# pse84 register map
Vendor: Infineon Technologies; Series: PSE84; File version: 1.0
CPU: CM33 r0p1, little endian, MPU, FPU, VTOR, 3 interrupt priority bits
Registers are 32-bit, read-write, reset 0x0 unless marked. A register's access mark holds for its fields unless they carry their own. Offsets are from the block's base; [hi:lo] are bit positions; lines under a group give offsets from that group; {n}, {i} and the like mark numbered series; 'fields as' and 'values as' point back to an identical list; <NAME> marks a mode.

## PWRMODE — SRSS Power Mode Control Registers
Base 0x42410000
{0x0+0x10*i} PD[{i}] (i=0..15) group — Power Domain Dependency Sense Register
  0x00 PD_SENSE reset not defined — Dependency Sense Register
    [15:0] PD_ON — Each bit <i> indicates whether PD<j> is directly kept on when PD<i> is on. Indirect dependency is still possible if multiple direct dependencies work together to create a transitive relationship. For example, if PD1 depends upon PD2; and PD2 dpends upon PD3; then PD1 indirectly depends upon PD3 regardless of whether there is a direct dependency from PD3 to PD1. Some bits are implemented as constants, and some bits are implemented as user-configurable registers. Refer to PD_SPT register to see how each bit is implemented.
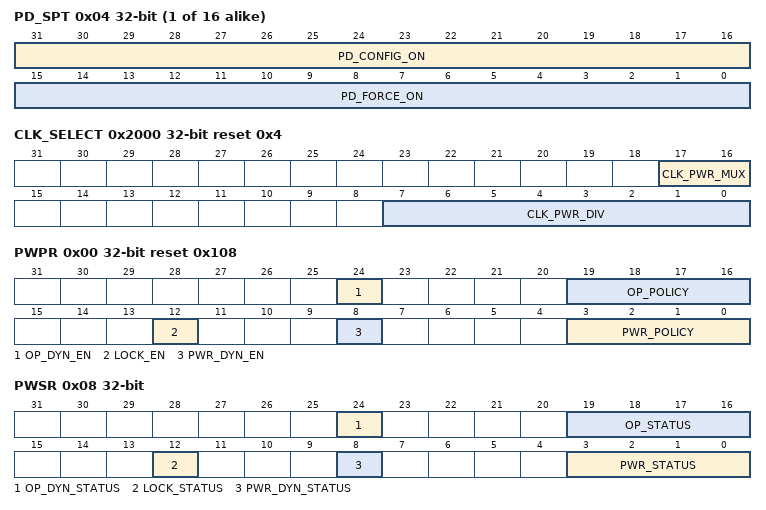
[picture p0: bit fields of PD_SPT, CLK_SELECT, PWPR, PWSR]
  0x04 PD_SPT ro reset not defined — Dependency Support Register
    [31:16] PD_CONFIG_ON — Each bit <i> indicates whether PD<j> can be configured on when PD<i> is on.
    [15:0] PD_FORCE_ON — Each bit <i> indicates whether PD<j> is always kept on when PD<i> is on for sense bits that are not configurable. For configurable bits, this indicates the reset value of the configurable bit.
0x1000 PPU_MAIN group — Power Policy Unit for Active Domain
  0x00 PPU_MAIN group — Power Policy Unit Registers for the main power domain (VCCACT_PD)
    0x00 PWPR reset 0x108 — Power Policy Register
      [24] OP_DYN_EN
      [19:16] OP_POLICY
      [12] LOCK_EN
      [8] PWR_DYN_EN — Power mode dynamic transition enable. For main PPU, keep this bit 1.
      [3:0] PWR_POLICY — Power mode policy. When static power mode transitions are enabled, PWR_DYN_EN is set to 0, this is the target power mode for the PPU. When dynamic power mode transitions are enabled, PWR_DYN_EN is set to 1, this is the minimum power mode for the PPU. This PPU supports the following modes: OFF(0), MEM_RET(2), FULL_RET(5), ON(8). Do not use WARM_RST(9) or other unsupported modes.
    0x04 PMER — Power Mode Emulation Register
      [0] EMU_EN
    0x08 PWSR ro — Power Status Register
      [24] OP_DYN_STATUS
      [19:16] OP_STATUS
      [12] LOCK_STATUS
      [8] PWR_DYN_STATUS — Power mode dynamic transition status. When set to 1 power mode dynamic transitions are enabled. There might be a delay in dynamic transitions becoming active or inactive if the PPU is transitioning when PWR_DYN_EN is programmed.
      [3:0] PWR_STATUS — Power mode status. These bits reflect the current power mode of the PPU. See PPU_PWPR.PWR_POLICY for power mode enumeration.
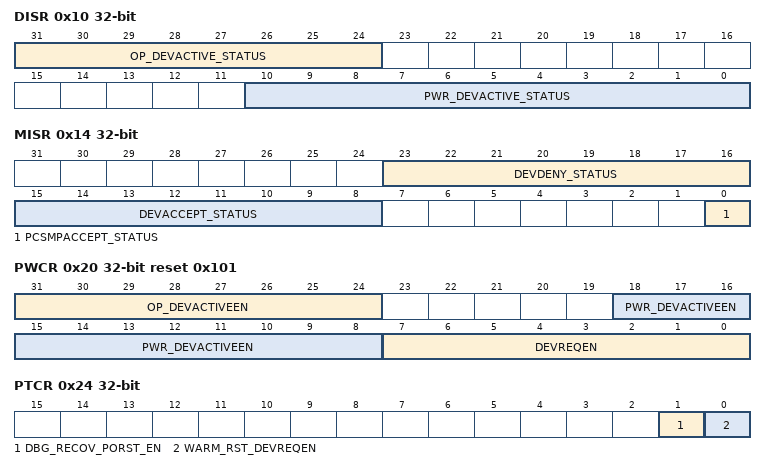
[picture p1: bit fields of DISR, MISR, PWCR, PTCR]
    0x10 DISR ro — Device Interface Input Current Status Register
      [31:24] OP_DEVACTIVE_STATUS
      [10:0] PWR_DEVACTIVE_STATUS — Status of the power mode DEVACTIVE inputs. There is one bit for each device interface Q-Channel DEVQACTIVE. For example, bit 0 is for Q-channel device 0 DEVQACTIVE. Refer to PPU_IDR0.DEVCHAN for device channel enumeration.
    0x14 MISR ro — Miscellaneous Input Current Status Register
      [23:16] DEVDENY_STATUS — Status of the device interface DEVDENY inputs. There is one bit for each device interface DEVQDENY. For example, bit 16 is for Q-Channel 0 DEVQDENY, and bit 17 for Q-Channel 1 DEVQDENY. Refer to PPU_IDR0.DEVCHAN for device channel enumeration.
      [15:8] DEVACCEPT_STATUS — Status of the device interface DEVACCEPT inputs. There is one bit for each device interface DEVQACCEPTn. For example, bit 8 is for Q-Channel 0 DEVQACCEPTn and bit 9 for Q-Channel 1 DEVQACCEPTn. Refer to PPU_IDR0.DEVCHAN for device channel enumeration.
      [0] PCSMPACCEPT_STATUS — The status of the PCSMPACCEPT input.
    0x18 STSR ro — Stored Status Register
      [7:0] STORED_DEVDENY — Status of the DEVDENY signals from the last device interface Q-Channel transition. For Q-Channel: There is one bit for each device interface DEVQDENY. For example, bit 0 is for Q-Channel 0 DEVQDENY, and bit 1 for Q-Channel 1 DEVQDENY. Refer to PPU_DISR.PWR_DEVACTIVE_STATUS for device enumeration.
    0x1C UNLK — Unlock register
      [0] UNLOCK
    0x20 PWCR reset 0x101 — Power Configuration Register
      [31:24] OP_DEVACTIVEEN
      [18:8] PWR_DEVACTIVEEN — These bits enable the power mode DEVACTIVE inputs. When a bit is to 1 the related DEVACTIVE input is enabled, when set to 0 it is disabled. All available bits are reset to 1. There is one bit for each device interface Q-Channel DEVQACTIVE. For example, bit 8 is for the Q-Channel 0 DEVQACTIVE, and bit 9 for the Q-Channel 1 DEVQACTIVE. Refer to PPU_IDR0.DEVCHAN for device channel enumeration.
      [7:0] DEVREQEN — When set to 1 enables the device interface handshake for transitions. All available bits are reset to 1. There is one bit for each device interface channel. For example, bit 0 is for Q-Channel 0, and bit 1 is for Q-Channel 1. Refer to PPU_IDR0.DEVCHAN for device channel enumeration.
    0x24 PTCR — Power Mode Transition Configuration Register
      [1] DBG_RECOV_PORST_EN
      [0] WARM_RST_DEVREQEN — Transition behavior between ON and WARM_RST. This bit should not be modified when the PPU is in WARM_RST, or if the PPU is performing a transition, otherwise PPU behavior is UNPREDICTABLE. 0: The PPU does not perform a device interface handshake when transitioning between ON and WARM_RST. 1: The PPU performs a device interface handshake when transitioning between ON and WARM_RST. This disables all Q-Channels for this transition.
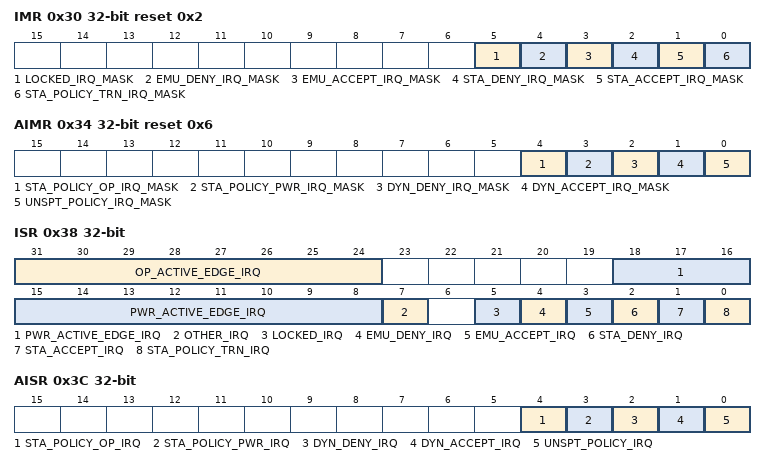
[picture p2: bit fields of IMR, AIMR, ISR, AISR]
    0x30 IMR reset 0x2 — Interrupt Mask Register
      [5] LOCKED_IRQ_MASK
      [4] EMU_DENY_IRQ_MASK
      [3] EMU_ACCEPT_IRQ_MASK
      [2] STA_DENY_IRQ_MASK — Static transition denial event mask.
      [1] STA_ACCEPT_IRQ_MASK — Static transition acceptance event mask. For main PPU, keep this bit 1 to mask the event, otherwise the interrupt may trigger a wakeup.
      [0] STA_POLICY_TRN_IRQ_MASK — Static full policy transition completion event mask. For main PPU, this bit has no function because no static transitions are supported (see PWPR.PWR_DYN_EN).
    0x34 AIMR reset 0x6 — Additional Interrupt Mask Register
      [4] STA_POLICY_OP_IRQ_MASK
      [3] STA_POLICY_PWR_IRQ_MASK
      [2] DYN_DENY_IRQ_MASK — Dynamic transition denial event mask.
      [1] DYN_ACCEPT_IRQ_MASK — Dynamic transition acceptance event mask. For main PPU, keep this bit 1 to mask the event, otherwise the interrupt that occurs when entering a low power mode may trigger a wakeup.
      [0] UNSPT_POLICY_IRQ_MASK — Unsupported Policy event mask.
    0x38 ISR — Interrupt Status Register
      [31:24] OP_ACTIVE_EDGE_IRQ
      [18:8] PWR_ACTIVE_EDGE_IRQ
      [7] OTHER_IRQ ro — Indicates there is an interrupt event pending in the Additional Interrupt Status Register (PPU_AISR).
      [5] LOCKED_IRQ
      [4] EMU_DENY_IRQ
      [3] EMU_ACCEPT_IRQ
      [2] STA_DENY_IRQ — Static transition denial event status.
      [1] STA_ACCEPT_IRQ — Static transition acceptance event status.
      [0] STA_POLICY_TRN_IRQ — Static full policy transition completion event status.
    0x3C AISR — Additional Interrupt Status Register
      [4] STA_POLICY_OP_IRQ
      [3] STA_POLICY_PWR_IRQ
      [2] DYN_DENY_IRQ — Dynamic transition denial event status.
      [1] DYN_ACCEPT_IRQ — Dynamic transition acceptance event status.
      [0] UNSPT_POLICY_IRQ — Unsupported Policy event status.
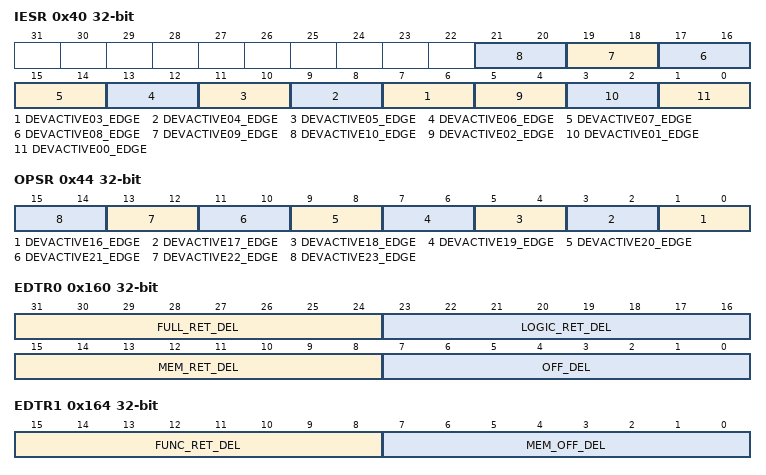
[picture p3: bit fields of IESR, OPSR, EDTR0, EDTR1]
    0x40 IESR — Input Edge Sensitivity Register
      [2n+1:2n] DEVACTIVE{n:02}_EDGE (n=3..10)
      [5:4] DEVACTIVE02_EDGE — DEVACTIVE 2 edge sensitivity.
      [3:2] DEVACTIVE01_EDGE — DEVACTIVE 1 edge sensitivity.
      [1:0] DEVACTIVE00_EDGE — DEVACTIVE 0 edge sensitivity.
    0x44 OPSR — Operating Mode Active Edge Sensitivity Register
      [2n-31:2n-32] DEVACTIVE{n}_EDGE (n=16..23)
    0x50 FUNRR — Functional Retention RAM Configuration Register
      [7:0] FUNC_RET_RAM_CFG
    0x54 FULRR — Full Retention RAM Configuration Register
      [7:0] FULL_RET_RAM_CFG
    0x58 MEMRR — Memory Retention RAM Configuration Register
      [7:0] MEM_RET_RAM_CFG
    0x160 EDTR0 — Power Mode Entry Delay Register 0
      [31:24] FULL_RET_DEL, [23:16] LOGIC_RET_DEL, [15:8] MEM_RET_DEL, [7:0] OFF_DEL
    0x164 EDTR1 — Power Mode Entry Delay Register 1
      [15:8] FUNC_RET_DEL, [7:0] MEM_OFF_DEL
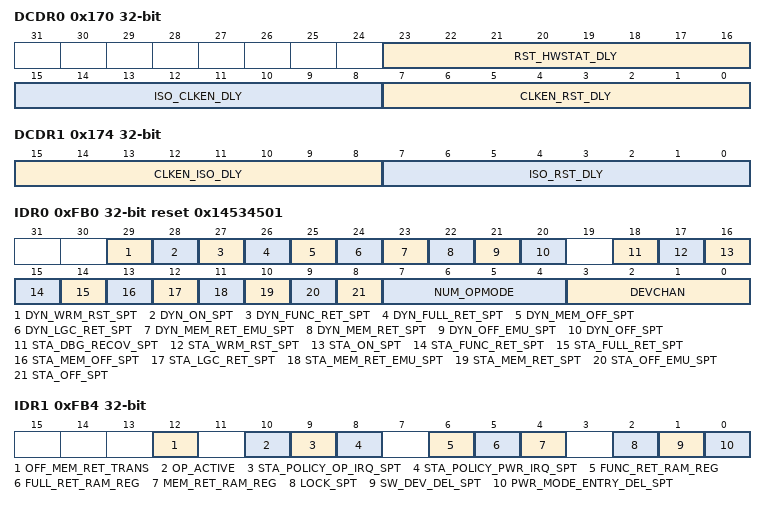
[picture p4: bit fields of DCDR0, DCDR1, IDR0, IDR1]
    0x170 DCDR0 ro — Device Control Delay Configuration Register 0
      [23:16] RST_HWSTAT_DLY, [15:8] ISO_CLKEN_DLY, [7:0] CLKEN_RST_DLY
    0x174 DCDR1 ro — Device Control Delay Configuration Register 1
      [15:8] CLKEN_ISO_DLY, [7:0] ISO_RST_DLY
    0xFB0 IDR0 ro reset 0x14534501 — PPU Identification Register 0
      [29] DYN_WRM_RST_SPT — Dynamic WARM_RST support.
      [28] DYN_ON_SPT — Dynamic ON support.
      [27] DYN_FUNC_RET_SPT — Dynamic FUNC_RET support.
      [26] DYN_FULL_RET_SPT — Dynamic FULL_RET support.
      [25] DYN_MEM_OFF_SPT — Dynamic MEM_OFF support.
      [24] DYN_LGC_RET_SPT — Dynamic LOGIC_RET support.
      [23] DYN_MEM_RET_EMU_SPT — Dynamic MEM_RET_EMU support
      [22] DYN_MEM_RET_SPT — Dynamic MEM_RET support.
      [21] DYN_OFF_EMU_SPT — Dynamic OFF_EMU support.
      [20] DYN_OFF_SPT — Dynamic OFF support.
      [18] STA_DBG_RECOV_SPT — DBG_RECOV support.
      [17] STA_WRM_RST_SPT — WARM_RST support. Ignore this bit. Do not use WARM_RST.
      [16] STA_ON_SPT — ON support.
      [15] STA_FUNC_RET_SPT — FUNC_RET support.
      [14] STA_FULL_RET_SPT — FULL_RET support.
      [13] STA_MEM_OFF_SPT — MEM_OFF support.
      [12] STA_LGC_RET_SPT — LOGIC_RET support.
      [11] STA_MEM_RET_EMU_SPT — MEM_RET_EMU support.
      [10] STA_MEM_RET_SPT — MEM_RET support.
      [9] STA_OFF_EMU_SPT — OFF_EMU support.
      [8] STA_OFF_SPT — OFF support.
      [7:4] NUM_OPMODE — No. of operating modes supported is NUM_OPMODE + 1.
      [3:0] DEVCHAN — No. of Device Interface Channels. 0: This is a P-Channel PPU. Refer to PPU_IDR1.OP_ACTIVE for the number of DEVPACTIVE inputs and their meaning. non-zero: The value is the number of Q-Channels. The device enumeration is: Device 0: PDCM
    0xFB4 IDR1 ro — PPU Identification Register 1
      [12] OFF_MEM_RET_TRANS — OFF to MEM_RET direct transition. Indicates if direct transitions from OFF to MEM_RET and from OFF_EMU to MEM_RET_EMU are supported.
      [10] OP_ACTIVE
      [9] STA_POLICY_OP_IRQ_SPT — Operating policy transition completion event status.
      [8] STA_POLICY_PWR_IRQ_SPT — Power policy transition completion event status.
      [6] FUNC_RET_RAM_REG
      [5] FULL_RET_RAM_REG
      [4] MEM_RET_RAM_REG
      [2] LOCK_SPT — Lock and the lock interrupt event are supported.
      [1] SW_DEV_DEL_SPT — Software device delay control configuration support.
      [0] PWR_MODE_ENTRY_DEL_SPT — Power mode entry delay support.
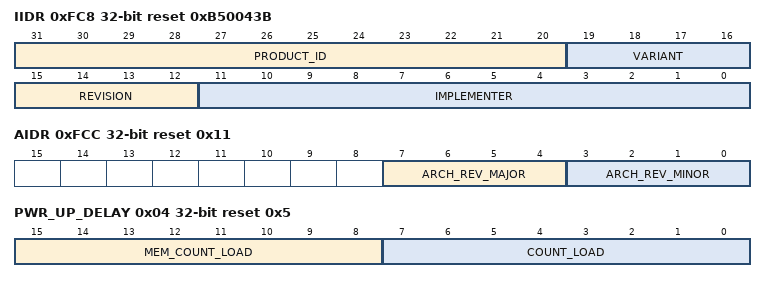
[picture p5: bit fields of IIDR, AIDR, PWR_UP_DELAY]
    0xFC8 IIDR ro reset 0xB50043B — Implementation Identification Register
      [31:20] PRODUCT_ID — PPU part identification.
      [19:16] VARIANT — Major revision of the product.
      [15:12] REVISION — Minor revision of the product.
      [11:0] IMPLEMENTER — Implementer identification. [11:8] The JEP106 continuation code of the implementer. [7] Always 0. [6:0] The JEP106 identity code of the implementer. For an Arm implementation, bits [11:0] are 0x43B.
    0xFCC AIDR ro reset 0x11 — Architecture Identification Register
      [7:4] ARCH_REV_MAJOR, [3:0] ARCH_REV_MINOR
0x2000 CLK_SELECT reset 0x4 — Clock Selection for Power Mode Components
  [17:16] CLK_PWR_MUX — Selects a source for the clock used by power control components. Note that not all products support all clock sources. Selecting a clock source that is not supported will result in undefined behavior. It takes four cycles of the originally selected clock to switch away from it. Do not disable the original clock during this time.
    0=IHO (IHO - Internal High-speed Oscillator); 1=IMO (IMO - Internal R/C Oscillator); 2=RSVD (N/A)
  [7:0] CLK_PWR_DIV — clk_pwr is generated by dividing the CLK_PWR_MUX selection by (CLK_PWR_DIV+1).
0x2004 PDCM_HWSTAT_IN ro — PPU Status input
  [15:0] PPU_HWSTAT_ON — Each bit represents the PPU 'ON' Status of connected PPU. 1: PPU is ON
0x2008 PDCM_PD_PRESENT ro — Mask for whether a PD is present in the PDCM
  [15:0] PRESENT
0x3000 PPU_PD1 group — Power Policy Unit for PD1 Active Domain
  0x00 PPU_MAIN group — Power Policy Unit Registers for the main power domain (VCCACT_PD)
    0x00 PWPR reset 0x100 — Power Policy Register
      fields as PPU_MAIN.PPU_MAIN.PWPR
    0x04 PMER — Power Mode Emulation Register
      [0] EMU_EN
    0x08 PWSR ro — Power Status Register
      fields as PPU_MAIN.PPU_MAIN.PWSR
    0x10 DISR ro — Device Interface Input Current Status Register
      fields as PPU_MAIN.PPU_MAIN.DISR
    0x14 MISR ro — Miscellaneous Input Current Status Register
      fields as PPU_MAIN.PPU_MAIN.MISR
    0x18 STSR ro — Stored Status Register
      fields as PPU_MAIN.PPU_MAIN.STSR
    0x1C UNLK — Unlock register
      [0] UNLOCK
    0x20 PWCR reset 0x101 — Power Configuration Register
      fields as PPU_MAIN.PPU_MAIN.PWCR
    0x24 PTCR — Power Mode Transition Configuration Register
      fields as PPU_MAIN.PPU_MAIN.PTCR
    0x30 IMR reset 0x2 — Interrupt Mask Register
      fields as PPU_MAIN.PPU_MAIN.IMR
    0x34 AIMR reset 0x6 — Additional Interrupt Mask Register
      fields as PPU_MAIN.PPU_MAIN.AIMR
    0x38 ISR — Interrupt Status Register
      fields as PPU_MAIN.PPU_MAIN.ISR
    0x3C AISR — Additional Interrupt Status Register
      fields as PPU_MAIN.PPU_MAIN.AISR
    0x40 IESR — Input Edge Sensitivity Register
      fields as PPU_MAIN.PPU_MAIN.IESR
    0x44 OPSR — Operating Mode Active Edge Sensitivity Register
      [2n-31:2n-32] DEVACTIVE{n}_EDGE (n=16..23)
    0x50 FUNRR — Functional Retention RAM Configuration Register
      [7:0] FUNC_RET_RAM_CFG
    0x54 FULRR — Full Retention RAM Configuration Register
      [7:0] FULL_RET_RAM_CFG
    0x58 MEMRR — Memory Retention RAM Configuration Register
      [7:0] MEM_RET_RAM_CFG
    0x160 EDTR0 — Power Mode Entry Delay Register 0
      fields as PPU_MAIN.PPU_MAIN.EDTR0
    0x164 EDTR1 — Power Mode Entry Delay Register 1
      [15:8] FUNC_RET_DEL, [7:0] MEM_OFF_DEL
    0x170 DCDR0 ro — Device Control Delay Configuration Register 0
      [23:16] RST_HWSTAT_DLY, [15:8] ISO_CLKEN_DLY, [7:0] CLKEN_RST_DLY
    0x174 DCDR1 ro — Device Control Delay Configuration Register 1
      [15:8] CLKEN_ISO_DLY, [7:0] ISO_RST_DLY
    0xFB0 IDR0 ro reset 0x14534501 — PPU Identification Register 0
      fields as PPU_MAIN.PPU_MAIN.IDR0
    0xFB4 IDR1 ro — PPU Identification Register 1
      fields as PPU_MAIN.PPU_MAIN.IDR1
    0xFC8 IIDR ro reset 0xB50043B — Implementation Identification Register
      fields as PPU_MAIN.PPU_MAIN.IIDR
    0xFCC AIDR ro reset 0x11 — Architecture Identification Register
      [7:4] ARCH_REV_MAJOR, [3:0] ARCH_REV_MINOR
0x4000 PD0_CTRL group — PD0 Power Domain Control Registers
  0x00 PD group — Power Domain Controller
    0x00 CTL — Power Domain Control
      [0] BLEED_EN — Activates bleed feature for the controlled power domain
    0x04 PWR_UP_DELAY reset 0x5 — Active switch weak enable to active switch strong enable delay
      [15:8] MEM_COUNT_LOAD — Load value for counter running on clk_pwr (10MHz) providing the timing from weak MEM switch enable to strong MEM switch enable. Default is 5 for ~500ns
      [7:0] COUNT_LOAD — Load value for counter running on clk_pwr (10MHz) providing the timing from weak ACTIVE switch enable to strong ACTIVE switch enable. Default is 5 for ~500ns
0x5000 PD1_CTRL group — PD1 Power Domain Control Registers
  0x00 PD group — Power Domain Controller
    0x00 CTL — Power Domain Control
      fields as PD0_CTRL.PD.CTL
    0x04 PWR_UP_DELAY reset 0x5 — Active switch weak enable to active switch strong enable delay
      fields as PD0_CTRL.PD.PWR_UP_DELAY
